VERSION "HIPBNYYYYYYYYYYYYYYYYYYYYYYYYYYYNNNNNNNNNN/4/%%%/4/'%**4NNN///"

NS_ :

BS_:

BU_: SensorCluster CANalyser

BO_ 1890 DIAG_REQ: 4 CANalyser
 SG_ DIAG_REQUEST : 0|4@1+ (1,0) [0|15] ""  SensorCluster
 SG_ RESET_REQUEST : 4|4@1+ (1,0) [0|15] ""  SensorCluster

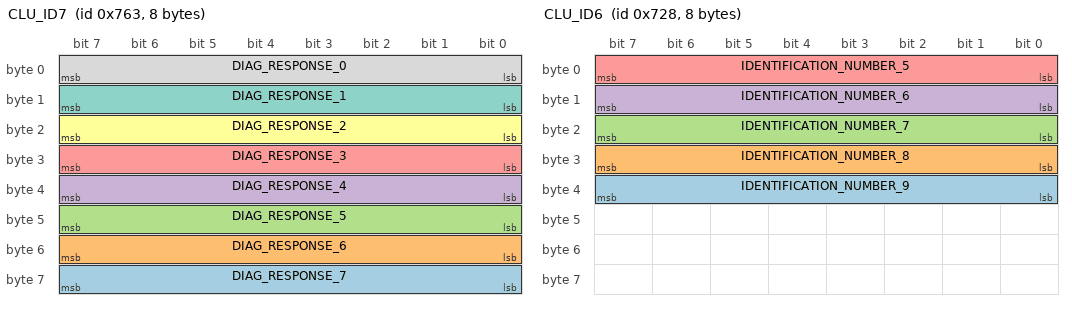
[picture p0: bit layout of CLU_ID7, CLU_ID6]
BO_ 1891 CLU_ID7: 8 SensorCluster
 SG_ DIAG_RESPONSE_7 : 56|8@1+ (1,0) [0|255] ""  CANalyser
 SG_ DIAG_RESPONSE_6 : 48|8@1+ (1,0) [0|255] ""  CANalyser
 SG_ DIAG_RESPONSE_5 : 40|8@1+ (1,0) [0|255] ""  CANalyser
 SG_ DIAG_RESPONSE_4 : 32|8@1+ (1,0) [0|255] ""  CANalyser
 SG_ DIAG_RESPONSE_3 : 24|8@1+ (1,0) [0|255] ""  CANalyser
 SG_ DIAG_RESPONSE_2 : 16|8@1+ (1,0) [0|255] ""  CANalyser
 SG_ DIAG_RESPONSE_1 : 8|8@1+ (1,0) [0|255] ""  CANalyser
 SG_ DIAG_RESPONSE_0 : 0|8@1+ (1,0) [0|255] ""  CANalyser

BO_ 1832 CLU_ID6: 8 SensorCluster
 SG_ IDENTIFICATION_NUMBER_9 : 32|8@1+ (1,0) [0|255] ""  CANalyser
 SG_ IDENTIFICATION_NUMBER_8 : 24|8@1+ (1,0) [0|255] ""  CANalyser
 SG_ IDENTIFICATION_NUMBER_7 : 16|8@1+ (1,0) [0|255] ""  CANalyser
 SG_ IDENTIFICATION_NUMBER_6 : 8|8@1+ (1,0) [0|255] ""  CANalyser
 SG_ IDENTIFICATION_NUMBER_5 : 0|8@1+ (1,0) [0|255] ""  CANalyser

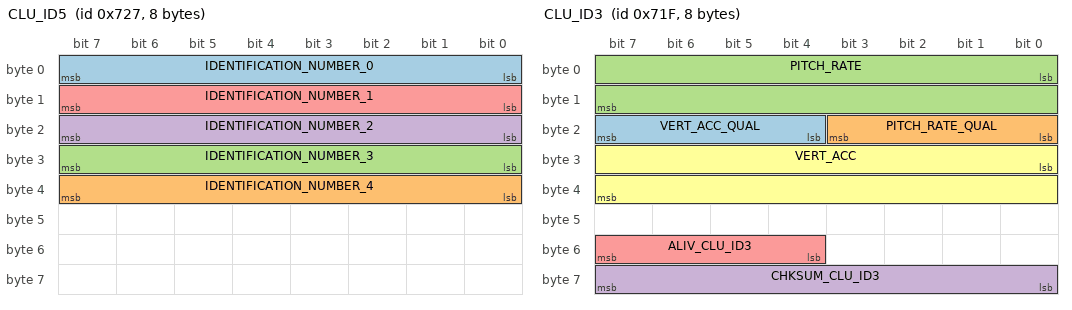
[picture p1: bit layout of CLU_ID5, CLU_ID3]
BO_ 1831 CLU_ID5: 8 SensorCluster
 SG_ IDENTIFICATION_NUMBER_0 : 0|8@1+ (1,0) [0|255] ""  CANalyser
 SG_ IDENTIFICATION_NUMBER_4 : 32|8@1+ (1,0) [0|255] ""  CANalyser
 SG_ IDENTIFICATION_NUMBER_3 : 24|8@1+ (1,0) [0|255] ""  CANalyser
 SG_ IDENTIFICATION_NUMBER_2 : 16|8@1+ (1,0) [0|255] ""  CANalyser
 SG_ IDENTIFICATION_NUMBER_1 : 8|8@1+ (1,0) [0|255] ""  CANalyser

BO_ 1823 CLU_ID3: 8 SensorCluster
 SG_ VERT_ACC_QUAL : 20|4@1+ (1,0) [0|15] ""  CANalyser
 SG_ PITCH_RATE_QUAL : 16|4@1+ (1,0) [0|15] ""  CANalyser
 SG_ PITCH_RATE : 0|16@1+ (0.005,-163.83) [-163.83|163.845] "°/s"  CANalyser
 SG_ CHKSUM_CLU_ID3 : 56|8@1+ (1,0) [0|255] ""  CANalyser
 SG_ ALIV_CLU_ID3 : 52|4@1+ (1,0) [0|15] ""  CANalyser
 SG_ VERT_ACC : 24|16@1+ (0.002,-65.532) [-65.532|65.538] "m/s2"  CANalyser

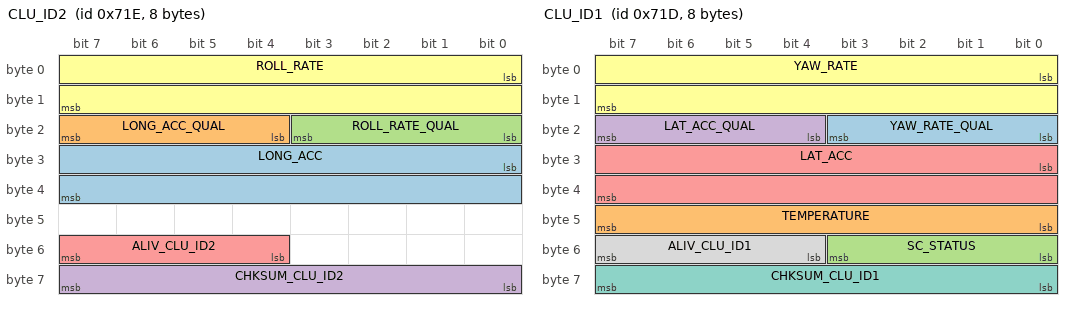
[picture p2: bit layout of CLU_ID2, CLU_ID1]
BO_ 1822 CLU_ID2: 8 SensorCluster
 SG_ LONG_ACC : 24|16@1+ (0.002,-65.532) [-65.532|65.538] "m/s2" Vector__XXX
 SG_ LONG_ACC_QUAL : 20|4@1+ (1,0) [0|15] ""  CANalyser
 SG_ ROLL_RATE_QUAL : 16|4@1+ (1,0) [0|15] ""  CANalyser
 SG_ CHKSUM_CLU_ID2 : 56|8@1+ (1,0) [0|255] ""  CANalyser
 SG_ ALIV_CLU_ID2 : 52|4@1+ (1,0) [0|15] ""  CANalyser
 SG_ ROLL_RATE : 0|16@1+ (0.005,-163.83) [-163.83|163.845] "°/s"  CANalyser

BO_ 1821 CLU_ID1: 8 SensorCluster
 SG_ YAW_RATE_QUAL : 16|4@1+ (1,0) [0|15] ""  CANalyser
 SG_ TEMPERATURE : 40|8@1+ (1,-50) [-50|205] "°C"  CANalyser
 SG_ SC_STATUS : 48|4@1+ (1,0) [0|15] ""  CANalyser
 SG_ LAT_ACC_QUAL : 20|4@1+ (1,0) [0|15] ""  CANalyser
 SG_ LAT_ACC : 24|16@1+ (0.002,-65.532) [-65.532|65.538] "m/s2"  CANalyser
 SG_ YAW_RATE : 0|16@1+ (0.005,-163.83) [-163.83|163.845] "°/s"  CANalyser
 SG_ CHKSUM_CLU_ID1 : 56|8@1+ (1,0) [0|255] ""  CANalyser
 SG_ ALIV_CLU_ID1 : 52|4@1+ (1,0) [0|15] ""  CANalyser

CM_ BU_ CANalyser "CANalyser ist der übergeordnete Netzknoten dieser Datenbasis";
BA_DEF_  "BusType" STRING ;
BA_DEF_DEF_  "BusType" "CAN";
VAL_ 1890 DIAG_REQUEST 15 "UNFILLED" 5 "HW_RELEASE_NUM" 4 "SW_RELEASE_NUM" 3 "SERIAL_NUM_P2" 2 "SERIAL_NUM_P1" 1 "MANUFACTURER_NUM" 0 "CUSTOMER_NUM" ;
VAL_ 1890 RESET_REQUEST 15 "UNFILLED" 14 "FAILURE" 13 "UNAVAILABLE" 1 "ON" 0 "OFF" ;
VAL_ 1823 VERT_ACC_QUAL 14 "NOT AVAILABLE" 15 "UNFILLED" 6 "INVALID" 4 "SUBSTITUTE" 2 "VALID" ;
VAL_ 1823 PITCH_RATE_QUAL 14 "NOT AVAILABLE" 15 "UNFILLED" 6 "INVALID" 4 "SUBSTITUTE" 2 "VALID" ;
VAL_ 1823 PITCH_RATE 65535 "UNFILLED" 65534 "INVALID" 65533 "NOT AVAILABLE" ;
VAL_ 1823 VERT_ACC 65535 "UNFILLED" 65534 "INVALID" 65533 "NOT AVAILABLE" ;
VAL_ 1822 LONG_ACC 65535 "UNFILLED" 65534 "INVALID" 65533 "NOT AVAILABLE" ;
VAL_ 1822 LONG_ACC_QUAL 14 "NOT AVAILABLE" 15 "UNFILLED" 6 "INVALID" 4 "SUBSTITUTE" 2 "VALID" ;
VAL_ 1822 ROLL_RATE_QUAL 14 "NOT AVAILABLE" 15 "UNFILLED" 6 "INVALID" 4 "SUBSTITUTE" 2 "VALID" ;
VAL_ 1822 ROLL_RATE 65535 "UNFILLED" 65534 "INVALID" 65533 "NOT AVAILABLE" ;
VAL_ 1821 YAW_RATE_QUAL 14 "NOT AVAILABLE" 15 "UNFILLED" 6 "INVALID" 4 "SUBSTITUTE" 2 "VALID" ;
VAL_ 1821 SC_STATUS 15 "UNFILLED" 14 "FUNC_ERROR" 13 "FUNC_NOT_AVAILABLE" 5 "SYNC_FAIL" 4 "SYNC_UNDERFLOW" 3 "OVERVOLTAGE" 2 "UNDERVOLTAGE" 0 "NO_MISTAKE" ;
VAL_ 1821 LAT_ACC_QUAL 14 "NOT AVAILABLE" 15 "UNFILLED" 6 "INVALID" 4 "SUBSTITUTE" 2 "VALID" ;
VAL_ 1821 LAT_ACC 65535 "UNFILLED" 65534 "INVALID" 65533 "NOT AVAILABLE" ;
VAL_ 1821 YAW_RATE 65535 "UNFILLED" 65534 "INVALID" 65533 "NOT AVAILABLE" ;
